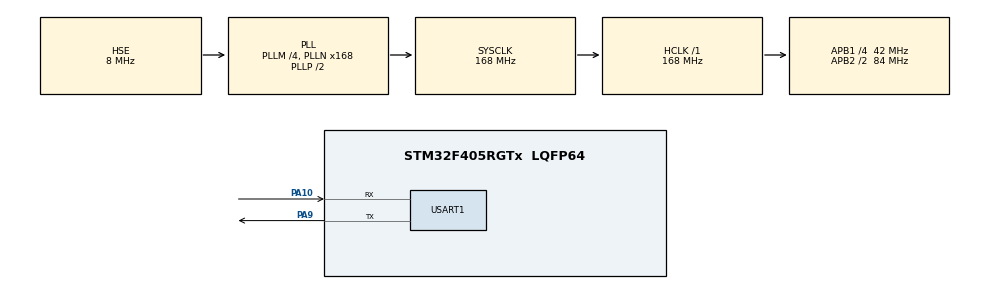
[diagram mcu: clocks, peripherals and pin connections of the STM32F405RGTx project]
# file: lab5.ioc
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Mcu.Family=STM32F4
Mcu.Name=STM32F405RGTx
Mcu.Package=LQFP64
NVIC.PriorityGroup=NVIC_PRIORITYGROUP_4
PA10.Mode=Asynchronous
PA10.Signal=USART1_RX
PA13.Mode=Serial_Wire
PA13.Signal=SYS_JTMS-SWDIO
PA14.Mode=Serial_Wire
PA14.Signal=SYS_JTCK-SWCLK
PA9.Mode=Asynchronous
PA9.Signal=USART1_TX
PH0-OSC_IN.Mode=HSE-External-Oscillator
PH0-OSC_IN.Signal=RCC_OSC_IN
PH1-OSC_OUT.Mode=HSE-External-Oscillator
PH1-OSC_OUT.Signal=RCC_OSC_OUT
ProjectManager.HeapSize=0x200
ProjectManager.StackSize=0x400
ProjectManager.TargetToolchain=STM32CubeIDE
RCC.48MHZClocksFreq_Value=84000000
RCC.AHBFreq_Value=168000000
RCC.APB1CLKDivider=RCC_HCLK_DIV4
RCC.APB1Freq_Value=42000000
RCC.APB1TimFreq_Value=84000000
RCC.APB2CLKDivider=RCC_HCLK_DIV2
RCC.APB2Freq_Value=84000000
RCC.APB2TimFreq_Value=168000000
RCC.CortexFreq_Value=168000000
RCC.HCLKFreq_Value=168000000
RCC.HSE_VALUE=8000000
RCC.HSI_VALUE=16000000
RCC.LSE_VALUE=32768
RCC.PLLM=4
RCC.PLLN=168
RCC.PLLSourceVirtual=RCC_PLLSOURCE_HSE
RCC.SYSCLKFreq_VALUE=168000000
RCC.SYSCLKSource=RCC_SYSCLKSOURCE_PLLCLK
RCC.VCOOutputFreq_Value=336000000
USART1.VirtualMode=VM_ASYNC
board=custom

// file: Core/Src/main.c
/* USER CODE BEGIN Header */
/**
  ******************************************************************************
  * @file           : main.c
  * @brief          : Main program body
  ******************************************************************************
  * @attention
  *
  * Copyright (c) 2022 STMicroelectronics.
  * All rights reserved.
  *
  * This software is licensed under terms that can be found in the LICENSE file
  * in the root directory of this software component.
  * If no LICENSE file comes with this software, it is provided AS-IS.
  *
  ******************************************************************************
  */
/* USER CODE END Header */
#include "main.h"

/* USER CODE BEGIN Includes */
#include <stdio.h>
#include <string.h>

/* USER CODE END Includes */

/* USER CODE BEGIN PD */
/* Base address of the Flash sectors */
#define ADDR_FLASH_SECTOR_0     ((uint32_t)0x08000000) /* Base @ of Sector 0, 16 Kbytes */
#define ADDR_FLASH_SECTOR_1     ((uint32_t)0x08004000) /* Base @ of Sector 1, 16 Kbytes */
#define ADDR_FLASH_SECTOR_2     ((uint32_t)0x08008000) /* Base @ of Sector 2, 16 Kbytes */
#define ADDR_FLASH_SECTOR_3     ((uint32_t)0x0800C000) /* Base @ of Sector 3, 16 Kbytes */
#define ADDR_FLASH_SECTOR_4     ((uint32_t)0x08010000) /* Base @ of Sector 4, 64 Kbytes */
#define ADDR_FLASH_SECTOR_5     ((uint32_t)0x08020000) /* Base @ of Sector 5, 128 Kbytes */
#define ADDR_FLASH_SECTOR_6     ((uint32_t)0x08040000) /* Base @ of Sector 6, 128 Kbytes */
#define ADDR_FLASH_SECTOR_7     ((uint32_t)0x08060000) /* Base @ of Sector 7, 128 Kbytes */
#define ADDR_FLASH_SECTOR_8     ((uint32_t)0x08080000) /* Base @ of Sector 8, 128 Kbytes */
#define ADDR_FLASH_SECTOR_9     ((uint32_t)0x080A0000) /* Base @ of Sector 9, 128 Kbytes */
#define ADDR_FLASH_SECTOR_10    ((uint32_t)0x080C0000) /* Base @ of Sector 10, 128 Kbytes */
#define ADDR_FLASH_SECTOR_11    ((uint32_t)0x080E0000) /* Base @ of Sector 11, 128 Kbytes */

#define FLASH_Sector_0     ((uint16_t)0x0000) /*!< Sector Number 0 */
#define FLASH_Sector_1     ((uint16_t)0x0008) /*!< Sector Number 1 */
#define FLASH_Sector_2     ((uint16_t)0x0010) /*!< Sector Number 2 */
#define FLASH_Sector_3     ((uint16_t)0x0018) /*!< Sector Number 3 */
#define FLASH_Sector_4     ((uint16_t)0x0020) /*!< Sector Number 4 */
#define FLASH_Sector_5     ((uint16_t)0x0028) /*!< Sector Number 5 */
#define FLASH_Sector_6     ((uint16_t)0x0030) /*!< Sector Number 6 */
#define FLASH_Sector_7     ((uint16_t)0x0038) /*!< Sector Number 7 */
#define FLASH_Sector_8     ((uint16_t)0x0040) /*!< Sector Number 8 */
#define FLASH_Sector_9     ((uint16_t)0x0048) /*!< Sector Number 9 */
#define FLASH_Sector_10    ((uint16_t)0x0050) /*!< Sector Number 10 */
#define FLASH_Sector_11    ((uint16_t)0x0058) /*!< Sector Number 11 */
/* USER CODE END PD */

UART_HandleTypeDef huart1;

void SystemClock_Config(void);
static void MX_GPIO_Init(void);
static void MX_USART1_UART_Init(void);
/* USER CODE BEGIN PFP */
#ifdef __GNUC__
/* With GCC/RAISONANCE, small printf (option LD Linker->Libraries->Small printf
 set to 'Yes') calls __io_putchar() */
#define PUTCHAR_PROTOTYPE int __io_putchar(int ch)
#else
 #define PUTCHAR_PROTOTYPE int fputc(int ch, FILE *f)
#endif /* __GNUC__ */

/* USER CODE END PFP */

/* USER CODE BEGIN 0 */

static uint32_t GetSector(uint32_t Address)
{
  uint32_t sector = 0;

  if((Address < ADDR_FLASH_SECTOR_1) && (Address >= ADDR_FLASH_SECTOR_0))
  {
    sector = FLASH_SECTOR_0;
  }
  else if((Address < ADDR_FLASH_SECTOR_2) && (Address >= ADDR_FLASH_SECTOR_1))
  {
    sector = FLASH_SECTOR_1;
  }
  else if((Address < ADDR_FLASH_SECTOR_3) && (Address >= ADDR_FLASH_SECTOR_2))
  {
    sector = FLASH_SECTOR_2;
  }
  else if((Address < ADDR_FLASH_SECTOR_4) && (Address >= ADDR_FLASH_SECTOR_3))
  {
    sector = FLASH_SECTOR_3;
  }
  else if((Address < ADDR_FLASH_SECTOR_5) && (Address >= ADDR_FLASH_SECTOR_4))
  {
    sector = FLASH_SECTOR_4;
  }
  else if((Address < ADDR_FLASH_SECTOR_6) && (Address >= ADDR_FLASH_SECTOR_5))
  {
    sector = FLASH_SECTOR_5;
  }
  else if((Address < ADDR_FLASH_SECTOR_7) && (Address >= ADDR_FLASH_SECTOR_6))
  {
    sector = FLASH_SECTOR_6;
  }
  else if((Address < ADDR_FLASH_SECTOR_8) && (Address >= ADDR_FLASH_SECTOR_7))
  {
    sector = FLASH_SECTOR_7;
  }
  else if((Address < ADDR_FLASH_SECTOR_9) && (Address >= ADDR_FLASH_SECTOR_8))
  {
    sector = FLASH_SECTOR_8;
  }
  else if((Address < ADDR_FLASH_SECTOR_10) && (Address >= ADDR_FLASH_SECTOR_9))
  {
    sector = FLASH_SECTOR_9;
  }
  else if((Address < ADDR_FLASH_SECTOR_11) && (Address >= ADDR_FLASH_SECTOR_10))
  {
    sector = FLASH_SECTOR_10;
  }
  else /*(Address < FLASH_END_ADDR) && (Address >= ADDR_FLASH_SECTOR_11))*/
  {
    sector = FLASH_SECTOR_11;
  }
  return sector;
}
uint32_t Flash_Write_Data (uint32_t StartSectorAddress, uint32_t *Data, uint16_t numberofwords)
{

	static FLASH_EraseInitTypeDef EraseInitStruct;
	uint32_t SECTORError;
	int sofar=0;

	 /* Unlock the Flash to enable the flash control register access *************/
	  HAL_FLASH_Unlock();

	  /* Erase the user Flash area */

	  /* Get the number of sector to erase from 1st sector */

	  uint32_t StartSector = GetSector(StartSectorAddress);
	  uint32_t EndSectorAddress = StartSectorAddress + numberofwords*4;
	  uint32_t EndSector = GetSector(EndSectorAddress);

	  /* Fill EraseInit structure*/
	  EraseInitStruct.TypeErase     = FLASH_TYPEERASE_SECTORS;
	  EraseInitStruct.VoltageRange  = FLASH_VOLTAGE_RANGE_3;
	  EraseInitStruct.Sector        = StartSector;
	  EraseInitStruct.NbSectors     = (EndSector - StartSector) + 1;

	  /* Note: If an erase operation in Flash memory also concerns data in the data or instruction cache,
	     you have to make sure that these data are rewritten before they are accessed during code
	     execution. If this cannot be done safely, it is recommended to flush the caches by setting the
	     DCRST and ICRST bits in the FLASH_CR register. */
	  if (HAL_FLASHEx_Erase(&EraseInitStruct, &SECTORError) != HAL_OK)
	  {
		  return HAL_FLASH_GetError ();
	  }

	  /* Program the user Flash area word by word
	    (area defined by FLASH_USER_START_ADDR and FLASH_USER_END_ADDR) ***********/

	   while (sofar<numberofwords)
	   {
	     if (HAL_FLASH_Program(FLASH_TYPEPROGRAM_WORD, StartSectorAddress, Data[sofar]) == HAL_OK)
	     {
	    	 StartSectorAddress += 4;  // use StartPageAddress += 2 for half word and 8 for double word
	    	 sofar++;
	     }
	     else
	     {
	       /* Error occurred while writing data in Flash memory*/
	    	 return HAL_FLASH_GetError ();
	     }
	   }

	  /* Lock the Flash to disable the flash control register access (recommended
	     to protect the FLASH memory against possible unwanted operation) *********/
	  HAL_FLASH_Lock();

	   return 0;
}

void Flash_Read_Data (uint32_t StartSectorAddress, uint32_t *RxBuf, uint16_t numberofwords)
{
	while (1)
	{

		*RxBuf = *(__IO uint32_t *)StartSectorAddress;
		StartSectorAddress += 4;
		RxBuf++;
		if (!(numberofwords--)) break;
	}
}

void Convert_To_Str (uint32_t *Data, char *Buf)
{
	int numberofbytes = ((strlen((char *)Data)/4) + ((strlen((char *)Data) % 4) != 0)) *4;

	for (int i=0; i<numberofbytes; i++)
	{
		Buf[i] = Data[i/4]>>(8*(i%4));
	}
}

/* USER CODE END 0 */

int main(void)
{

  /* MCU Configuration--------------------------------------------------------*/

  /* Reset of all peripherals, Initializes the Flash interface and the Systick. */
  HAL_Init();

  /* Configure the system clock */
  SystemClock_Config();

  /* Initialize all configured peripherals */
  MX_GPIO_Init();
  MX_USART1_UART_Init();
  /* USER CODE BEGIN 2 */
  char *data = "Hello, We are access Flash Memory in the course CE437\r\n";
  char data100[5500] = "";
  for (int i = 0; i < 100; i++)
  {
	  strcat(data100, data);
  }

  uint32_t Rx_Data[1375];
  char string[1375];

  int numofwords = (strlen(data100)/4)+((strlen(data100)%4)!=0);

  Flash_Write_Data(ADDR_FLASH_SECTOR_11, (uint32_t *)data100, numofwords);
  Flash_Read_Data(ADDR_FLASH_SECTOR_11, Rx_Data, numofwords);
  Convert_To_Str(Rx_Data, string);
  printf("Data: %s \r\n", string);

  printf("Done...  \r\n");
  /* USER CODE END 2 */

  /* Infinite loop */
  while (1)
  {

  }
}

void SystemClock_Config(void)
{
  RCC_OscInitTypeDef RCC_OscInitStruct = {0};
  RCC_ClkInitTypeDef RCC_ClkInitStruct = {0};

  /** Configure the main internal regulator output voltage
  */
  __HAL_RCC_PWR_CLK_ENABLE();
  __HAL_PWR_VOLTAGESCALING_CONFIG(PWR_REGULATOR_VOLTAGE_SCALE1);

  /** Initializes the RCC Oscillators according to the specified parameters
  * in the RCC_OscInitTypeDef structure.
  */
  RCC_OscInitStruct.OscillatorType = RCC_OSCILLATORTYPE_HSE;
  RCC_OscInitStruct.HSEState = RCC_HSE_ON;
  RCC_OscInitStruct.PLL.PLLState = RCC_PLL_ON;
  RCC_OscInitStruct.PLL.PLLSource = RCC_PLLSOURCE_HSE;
  RCC_OscInitStruct.PLL.PLLM = 4;
  RCC_OscInitStruct.PLL.PLLN = 168;
  RCC_OscInitStruct.PLL.PLLP = RCC_PLLP_DIV2;
  RCC_OscInitStruct.PLL.PLLQ = 4;
  if (HAL_RCC_OscConfig(&RCC_OscInitStruct) != HAL_OK)
  {
    Error_Handler();
  }

  /** Initializes the CPU, AHB and APB buses clocks
  */
  RCC_ClkInitStruct.ClockType = RCC_CLOCKTYPE_HCLK|RCC_CLOCKTYPE_SYSCLK
                              |RCC_CLOCKTYPE_PCLK1|RCC_CLOCKTYPE_PCLK2;
  RCC_ClkInitStruct.SYSCLKSource = RCC_SYSCLKSOURCE_PLLCLK;
  RCC_ClkInitStruct.AHBCLKDivider = RCC_SYSCLK_DIV1;
  RCC_ClkInitStruct.APB1CLKDivider = RCC_HCLK_DIV4;
  RCC_ClkInitStruct.APB2CLKDivider = RCC_HCLK_DIV2;

  if (HAL_RCC_ClockConfig(&RCC_ClkInitStruct, FLASH_LATENCY_5) != HAL_OK)
  {
    Error_Handler();
  }
}

static void MX_USART1_UART_Init(void)
{

  huart1.Instance = USART1;
  huart1.Init.BaudRate = 115200;
  huart1.Init.WordLength = UART_WORDLENGTH_8B;
  huart1.Init.StopBits = UART_STOPBITS_1;
  huart1.Init.Parity = UART_PARITY_NONE;
  huart1.Init.Mode = UART_MODE_TX_RX;
  huart1.Init.HwFlowCtl = UART_HWCONTROL_NONE;
  huart1.Init.OverSampling = UART_OVERSAMPLING_16;
  if (HAL_UART_Init(&huart1) != HAL_OK)
  {
    Error_Handler();
  }

}

static void MX_GPIO_Init(void)
{

  /* GPIO Ports Clock Enable */
  __HAL_RCC_GPIOH_CLK_ENABLE();
  __HAL_RCC_GPIOA_CLK_ENABLE();

}

/* USER CODE BEGIN 4 */
/**
 * @brief Retargets the C library printf function to the USART.
 * @param None
 * @retval None
 */
PUTCHAR_PROTOTYPE
{
  /* Place your implementation of fputc here */
  /* e.g. write a character to the USART */
  HAL_UART_Transmit(&huart1, (uint8_t*) &ch, 1, 100);
  return ch;
}

/* USER CODE END 4 */

void Error_Handler(void)
{
  __disable_irq();
  while (1)
  {
  }
}
